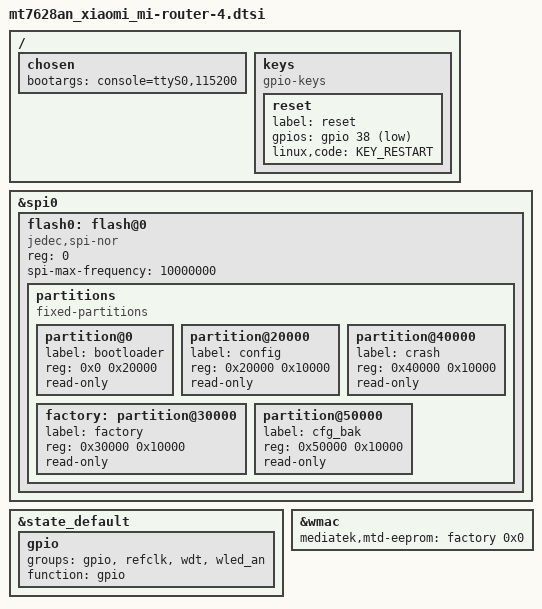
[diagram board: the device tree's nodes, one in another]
// SPDX-License-Identifier: GPL-2.0-or-later OR MIT

#include "mt7628an.dtsi"

#include <dt-bindings/gpio/gpio.h>
#include <dt-bindings/input/input.h>

/ {
	chosen {
		bootargs = "console=ttyS0,115200";
	};

	keys {
		compatible = "gpio-keys";

		reset {
			label = "reset";
			gpios = <&gpio 38 GPIO_ACTIVE_LOW>;
			linux,code = <KEY_RESTART>;
		};
	};
};

&spi0 {
	status = "okay";

	flash0: flash@0 {
		compatible = "jedec,spi-nor";
		reg = <0>;
		spi-max-frequency = <10000000>;

		partitions: partitions {
			compatible = "fixed-partitions";
			#address-cells = <1>;
			#size-cells = <1>;

			partition@0 {
				label = "bootloader";
				reg = <0x0 0x20000>;
				read-only;
			};

			partition@20000 {
				label = "config";
				reg = <0x20000 0x10000>;
				read-only;
			};

			factory: partition@30000 {
				label = "factory";
				reg = <0x30000 0x10000>;
				read-only;
			};

			partition@40000 {
				label = "crash";
				reg = <0x40000 0x10000>;
				read-only;
			};

			partition@50000 {
				label = "cfg_bak";
				reg = <0x50000 0x10000>;
				read-only;
			};

			/* additional partitions in DTS */
		};
	};
};

&state_default {
	gpio {
		groups = "gpio", "refclk", "wdt", "wled_an";
		function = "gpio";
	};
};

&wmac {
	status = "okay";

	mediatek,mtd-eeprom = <&factory 0x0>;
};
